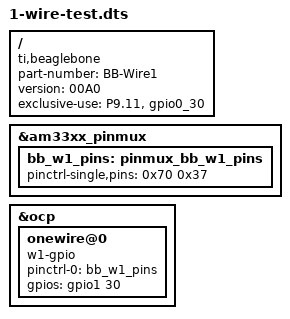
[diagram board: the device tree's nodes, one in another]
/*  
* Copyright (C) 2012 Texas Instruments Incorporated - http://www.ti.com/
*
* This program is free software; you can redistribute it and/or modify
* it under the terms of the GNU General Purpose License Version 2 as
* published by the Free Software Foundation
*
* Original from: github.com/jadonk/validation-scripts/blob/master/test-capemgr/ 
*
* Modified by Derek Molloy for the example on www.derekmolloy.ie
* that maps GPIO pins for the example
*/

/dts-v1/;
/plugin/;

/{
 compatible = "ti,beaglebone", "ti,beaglebone-black";
    part-number = "BB-Wire1";
    version = "00A0";
 
    exclusive-use = "P9.11","gpio0_30";
 
    fragment@0 {
        target = <&am33xx_pinmux>;
        __overlay__ {
             bb_w1_pins: pinmux_bb_w1_pins {
                 pinctrl-single,pins = < 0x70 0x37 >;
             };
        };
    };
 
    fragment@1 {
        target = <&ocp>;
        __overlay__ {
            onewire@0 {
                status          = "okay";
                compatible      = "w1-gpio";
                pinctrl-names   = "default";
                pinctrl-0       = <&bb_w1_pins>;
 
                gpios = <&gpio1 30 0>;
            };
        };
    };
};
